# MPU_AXI2OCP_MISC register map
Vendor: Texas Instruments
Peripheral module from a debugger description file (folder DRA74xP_75xP_76xP_77xP).
Registers are 32-bit, access per field, reset 0x4 unless marked. A register's access mark holds for its fields unless they carry their own. Offsets are as the file gives them; lines under a group give offsets from that group; [hi:lo] are bit positions; {n}, {i} and the like mark numbered series; 'fields as' and 'values as' point back to an identical list; <NAME> marks a mode.

## MPU_AXI2OCP_MISC
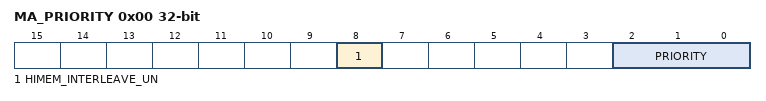
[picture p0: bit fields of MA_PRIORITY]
0x00 MA_PRIORITY — Memory adapter priority register. This register indicates the priority of memory access from MPU_MA to EMIF. This priority is used by EMIF in scheduling MPU_MA access to EMIF. 0x0 is highest priority and 0x7 is lowest priority.
  [8] HIMEM_INTERLEAVE_UN rw
  [2:0] PRIORITY rw — MPU_MA priority value
